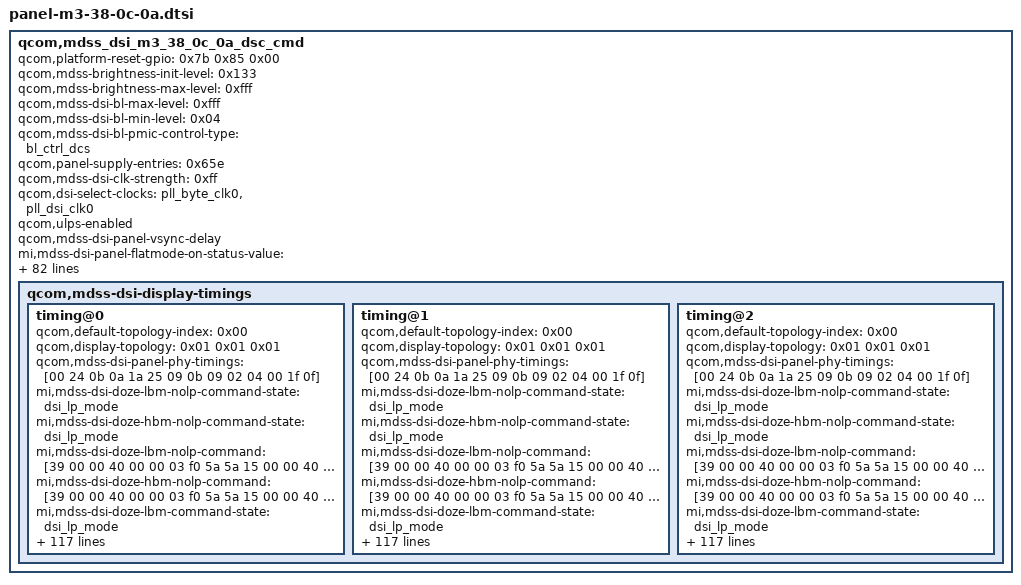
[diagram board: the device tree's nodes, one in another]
			qcom,mdss_dsi_m3_38_0c_0a_dsc_cmd {
				phandle = <0x676>;
				qcom,platform-reset-gpio = <0x7b 0x85 0x00>;
				qcom,mdss-brightness-init-level = <0x133>;
				qcom,mdss-brightness-max-level = <0xfff>;
				qcom,mdss-dsi-bl-max-level = <0xfff>;
				qcom,mdss-dsi-bl-min-level = <0x04>;
				qcom,mdss-dsi-bl-pmic-control-type = "bl_ctrl_dcs";
				qcom,panel-supply-entries = <0x65e>;
				qcom,mdss-dsi-clk-strength = <0xff>;
				qcom,dsi-select-clocks = "pll_byte_clk0", "pll_dsi_clk0";
				qcom,ulps-enabled;
				qcom,mdss-dsi-panel-vsync-delay;
				mi,mdss-dsi-panel-flatmode-on-status-value = <0x25>;
				mi,mdss-dsi-panel-flatmode-status-read-length = <0x01>;
				mi,mdss-dsi-panel-flatmode-status-offset-end-command-state = "dsi_lp_mode";
				mi,mdss-dsi-panel-flatmode-status-offset-end-command = [39 00 00 00 00 00 03 f0 a5 a5];
				mi,mdss-dsi-panel-flatmode-status-command-state = "dsi_lp_mode";
				mi,mdss-dsi-panel-flatmode-status-command = <0x6010001 0x192>;
				mi,mdss-dsi-panel-flatmode-status-offset-command-state = "dsi_lp_mode";
				mi,mdss-dsi-panel-flatmode-status-offset-command = [39 00 00 40 00 00 03 f0 5a 5a 39 00 00 00 00 00 04 b0 02 79 92];
				mi,flatmode-status-check-enabled;
				mi,normal-to-aod-doze-51reg-update-value = <0x995>;
				mi,dc-feature-type = "crc_skip_backlight";
				mi,thermal-dimming-flag;
				mi,dc-feature-enabled;
				mi,mdss-dsi-panel-dc-threshold = <0x1c2>;
				mi,mdss-fac-brightness-max-level = <0x7ff>;
				mi,mdss-dsi-fac-bl-max-level = <0x7ff>;
				mi,max-brightness-clone = <0x3fff>;
				mi,doze-lbm-dbv-level = <0x15>;
				mi,doze-hbm-dbv-level = <0xf3>;
				mi,panel-on-dimming-delay = <0x78>;
				mi,mdss-dsi-panel-wp-read-length = <0x04>;
				mi,mdss-dsi-panel-wp-read-command-state = "dsi_lp_mode";
				mi,mdss-dsi-panel-wp-read-command = <0x6010001 0x1a1>;
				mi,need-fod-animal-in-normal-enabled;
				mi,fod-low-brightness-lux-threshold = <0x01>;
				mi,fod-low-brightness-clone-threshold = <0x19b>;
				mi,local-hbm-ui-ready-delay-num-frame = <0x03>;
				mi,local-hbm-enabled;
				mi,panel-id = "", "", "M3", "8\f";
				mi,esd-err-irq-gpio = <0x7b 0x31 0x2008>;
				qcom,mdss-dsi-panel-blackness-level = <0xc9e>;
				qcom,mdss-dsi-panel-peak-brightness = <0x401640>;
				qcom,mdss-dsi-panel-hdr-color-primaries = <0x38a4 0x3c8c 0x7d00 0x4268 0x3c8c 0x7530 0x1f40 0xbb8>;
				qcom,mdss-dsi-panel-hdr-enabled;
				qcom,mdss-dsi-dma-schedule-window = <0x32>;
				qcom,mdss-dsi-dma-schedule-line = <0x01>;
				qcom,bl-update-flag = "delay_until_first_frame";
				qcom,mdss-dsi-bl-inverted-dbv;
				qcom,mdss-dsi-lp11-init;
				qcom,mdss-dsi-tx-eot-append;
				qcom,mdss-dsi-te-using-te-pin;
				qcom,mdss-dsi-te-check-enable;
				qcom,mdss-dsi-te-dcs-command = <0x01>;
				qcom,mdss-dsi-wr-mem-continue = <0x3c>;
				qcom,mdss-dsi-wr-mem-start = <0x2c>;
				qcom,mdss-dsi-te-pin-select = <0x01>;
				qcom,mdss-pan-physical-height-dimension = <0x93>;
				qcom,mdss-pan-physical-width-dimension = <0x42>;
				qcom,mdss-dsi-reset-sequence = <0x00 0x01 0x01 0x0a>;
				qcom,mdss-dsi-mdp-trigger = "none";
				qcom,mdss-dsi-dma-trigger = "trigger_sw";
				qcom,mdss-dsi-lane-3-state;
				qcom,mdss-dsi-lane-2-state;
				qcom,mdss-dsi-lane-1-state;
				qcom,mdss-dsi-lane-0-state;
				qcom,mdss-dsi-bllp-power-mode;
				qcom,mdss-dsi-bllp-eof-power-mode;
				qcom,mdss-dsi-lane-map = "lane_map_0123";
				qcom,mdss-dsi-traffic-mode = "burst_mode";
				qcom,dsi-phy-num = <0x00>;
				qcom,dsi-ctrl-num = <0x00>;
				qcom,mdss-dsi-border-color = <0x00>;
				qcom,mdss-dsi-underflow-color = <0xff>;
				qcom,mdss-dsi-color-order = "rgb_swap_rgb";
				qcom,mdss-dsi-bpp = <0x18>;
				qcom,mdss-dsi-stream = <0x00>;
				qcom,mdss-dsi-virtual-channel-id = <0x00>;
				qcom,mdss-dsi-panel-type = "dsi_cmd_mode";
				qcom,mdss-dsi-panel-name = "xiaomi m3 38 0c 0a sec cmd mode dsc dsi panel";

				qcom,mdss-dsi-display-timings {

					timing@0 {
						qcom,default-topology-index = <0x00>;
						qcom,display-topology = <0x01 0x01 0x01>;
						qcom,mdss-dsi-panel-phy-timings = [00 24 0b 0a 1a 25 09 0b 09 02 04 00 1f 0f];
						mi,mdss-dsi-doze-lbm-nolp-command-state = "dsi_lp_mode";
						mi,mdss-dsi-doze-hbm-nolp-command-state = "dsi_lp_mode";
						mi,mdss-dsi-doze-lbm-nolp-command = [39 00 00 40 00 00 03 f0 5a 5a 15 00 00 40 00 00 02 60 08 15 00 00 40 00 00 02 53 20 39 00 00 40 00 00 03 51 00 15 15 00 00 40 00 00 02 f7 0f 39 00 00 00 22 00 03 f0 a5 a5];
						mi,mdss-dsi-doze-hbm-nolp-command = [39 00 00 40 00 00 03 f0 5a 5a 15 00 00 40 00 00 02 60 08 15 00 00 40 00 00 02 53 20 39 00 00 40 00 00 03 51 00 f3 15 00 00 40 00 00 02 f7 0f 39 00 00 00 22 00 03 f0 a5 a5];
						mi,mdss-dsi-doze-lbm-command-state = "dsi_lp_mode";
						mi,mdss-dsi-doze-lbm-command-update = <0x51 0x00 0x02>;
						mi,mdss-dsi-doze-lbm-command = [39 00 00 20 00 00 03 51 09 95 39 00 00 40 00 00 03 f0 5a 5a 15 00 00 40 00 00 02 53 24 39 00 00 40 00 00 03 51 00 aa 15 00 00 40 00 00 02 f7 0f 39 00 00 00 00 00 03 f0 a5 a5];
						mi,mdss-dsi-doze-hbm-command-state = "dsi_lp_mode";
						mi,mdss-dsi-doze-hbm-command-update = <0x51 0x00 0x02>;
						mi,mdss-dsi-doze-hbm-command = [39 00 00 20 00 00 03 51 09 95 39 00 00 40 00 00 03 f0 5a 5a 15 00 00 40 00 00 02 53 24 39 00 00 40 00 00 03 51 07 ff 15 00 00 40 00 00 02 f7 0f 39 00 00 00 00 00 03 f0 a5 a5];
						mi,mdss-dsi-local-hbm-off-to-hbm-command-state = "dsi_lp_mode";
						mi,mdss-dsi-local-hbm-off-to-hbm-command-update = <0x51 0x02 0x02>;
						mi,mdss-dsi-local-hbm-off-to-hbm-command = [39 00 00 40 00 00 03 f0 5a 5a 15 00 00 40 00 00 02 53 20 39 00 00 40 00 00 03 51 00 00 39 00 00 00 00 00 03 f0 a5 a5];
						mi,mdss-dsi-local-hbm-off-to-normal-command-state = "dsi_lp_mode";
						mi,mdss-dsi-local-hbm-off-to-normal-command = [39 00 00 40 00 00 03 f0 5a 5a 15 00 00 40 00 00 02 53 20 39 00 00 00 00 00 03 f0 a5 a5];
						mi,mdss-dsi-local-hbm-normal-green-500nit-command-state = "dsi_hs_mode";
						mi,mdss-dsi-local-hbm-normal-green-500nit-command = [39 00 00 40 00 00 03 f0 5a 5a 39 00 00 40 00 00 04 b0 03 87 92 39 00 00 40 00 00 11 92 02 00 00 00 00 00 19 a7 e4 29 e8 e8 21 c8 66 60 39 00 00 40 00 00 04 b0 02 b4 98 39 00 00 40 00 00 03 98 00 00 39 00 00 40 00 00 04 b0 01 75 98 39 00 00 40 00 00 13 98 00 40 14 02 80 52 0a 41 48 1c 27 ff 80 0f ff ff ff ff 39 00 00 40 00 00 04 b0 02 5f 98 39 00 00 40 00 00 13 98 00 40 6f 09 80 d1 11 d1 86 1c 21 c2 7f f8 00 ff ff ff 39 00 00 40 00 00 04 b0 01 61 98 39 00 00 40 00 00 06 98 05 82 00 d5 00 39 00 00 40 00 00 04 b0 01 66 98 39 00 00 40 00 00 06 98 05 82 00 d5 00 39 00 00 40 00 00 04 b0 01 70 98 39 00 00 40 00 00 06 98 09 9d ef ff 23 39 00 00 40 00 00 04 b0 01 bd 98 39 00 00 40 00 00 37 98 15 62 09 2c 63 c2 52 27 0a 80 08 00 80 08 00 80 08 00 15 62 09 2c 63 c2 52 27 0a 80 08 00 80 08 00 80 08 00 15 62 09 2c 63 c2 52 27 0a 80 08 00 80 08 00 80 08 00 39 00 00 40 00 00 04 b0 01 f3 98 39 00 00 40 00 00 37 98 15 62 09 2c 63 c2 52 27 0a 80 08 00 80 08 00 80 08 00 15 62 09 2c 63 c2 52 27 0a 80 08 00 80 08 00 80 08 00 15 62 09 2c 63 c2 52 27 0a 80 08 00 80 08 00 80 08 00 39 00 00 40 00 00 04 b0 02 71 98 39 00 00 40 00 00 37 98 14 c1 ee 2b 43 c2 52 67 0a 80 08 00 80 08 00 80 08 00 14 a1 f3 2b 43 c2 52 67 0f 80 08 00 80 08 00 80 08 00 14 d1 f9 2b 43 c2 52 67 0a 80 08 00 80 08 00 80 08 00 39 00 00 40 00 00 02 53 30 39 00 00 00 00 00 03 f0 a5 a5];
						mi,mdss-dsi-local-hbm-hlpm-white-110nit-command-state = "dsi_hs_mode";
						mi,mdss-dsi-local-hbm-hlpm-white-110nit-command = [39 00 00 40 00 00 03 f0 5a 5a 39 00 00 40 00 00 02 53 20 39 00 00 00 22 00 03 f0 a5 a5 39 00 00 40 00 00 03 f0 5a 5a 39 00 00 40 00 00 04 b0 03 87 92 39 00 00 40 00 00 11 92 02 00 00 00 00 00 19 a7 e4 29 e8 e8 21 c8 66 60 39 00 00 40 00 00 04 b0 02 b4 98 39 00 00 40 00 00 03 98 00 00 39 00 00 40 00 00 04 b0 01 75 98 39 00 00 40 00 00 13 98 00 40 14 02 80 52 0a 41 48 1c 27 ff 80 0f ff ff ff ff 39 00 00 40 00 00 04 b0 02 5f 98 39 00 00 40 00 00 13 98 00 40 6f 09 80 d1 11 d1 86 1c 21 c2 7f f8 00 ff ff ff 39 00 00 40 00 00 04 b0 01 61 98 39 00 00 40 00 00 06 98 07 78 9c 34 e9 39 00 00 40 00 00 04 b0 01 66 98 39 00 00 40 00 00 06 98 07 78 9c 34 e9 39 00 00 40 00 00 04 b0 01 70 98 39 00 00 40 00 00 06 98 09 9d ef ff 23 39 00 00 40 00 00 04 b0 01 bd 98 39 00 00 40 00 00 37 98 15 62 09 2c 63 c2 52 27 0a 80 08 00 80 08 00 80 08 00 15 62 09 2c 63 c2 52 27 0a 80 08 00 80 08 00 80 08 00 15 62 09 2c 63 c2 52 27 0a 80 08 00 80 08 00 80 08 00 39 00 00 40 00 00 04 b0 01 f3 98 39 00 00 40 00 00 37 98 15 62 09 2c 63 c2 52 27 0a 80 08 00 80 08 00 80 08 00 15 62 09 2c 63 c2 52 27 0a 80 08 00 80 08 00 80 08 00 15 62 09 2c 63 c2 52 27 0a 80 08 00 80 08 00 80 08 00 39 00 00 40 00 00 04 b0 02 71 98 39 00 00 40 00 00 37 98 14 c1 ee 2b 43 c2 52 67 0a 80 08 00 80 08 00 80 08 00 14 a1 f3 2b 43 c2 52 67 0f 80 08 00 80 08 00 80 08 00 14 d1 f9 2b 43 c2 52 67 0a 80 08 00 80 08 00 80 08 00 39 00 00 40 00 00 02 53 30 39 00 00 00 0a 00 03 f0 a5 a5];
						mi,mdss-dsi-local-hbm-normal-white-110nit-command-state = "dsi_hs_mode";
						mi,mdss-dsi-local-hbm-normal-white-110nit-command = [39 00 00 40 00 00 03 f0 5a 5a 39 00 00 40 00 00 04 b0 03 87 92 39 00 00 40 00 00 11 92 02 00 00 00 00 00 19 a7 e4 29 e8 e8 21 c8 66 60 39 00 00 40 00 00 04 b0 02 b4 98 39 00 00 40 00 00 03 98 00 00 39 00 00 40 00 00 04 b0 01 75 98 39 00 00 40 00 00 13 98 00 40 14 02 80 52 0a 41 48 1c 27 ff 80 0f ff ff ff ff 39 00 00 40 00 00 04 b0 02 5f 98 39 00 00 40 00 00 13 98 00 40 6f 09 80 d1 11 d1 86 1c 21 c2 7f f8 00 ff ff ff 39 00 00 40 00 00 04 b0 01 61 98 39 00 00 40 00 00 06 98 07 78 9c 34 e9 39 00 00 40 00 00 04 b0 01 66 98 39 00 00 40 00 00 06 98 07 78 9c 34 e9 39 00 00 40 00 00 04 b0 01 70 98 39 00 00 40 00 00 06 98 09 9d ef ff 23 39 00 00 40 00 00 04 b0 01 bd 98 39 00 00 40 00 00 37 98 15 62 09 2c 63 c2 52 27 0a 80 08 00 80 08 00 80 08 00 15 62 09 2c 63 c2 52 27 0a 80 08 00 80 08 00 80 08 00 15 62 09 2c 63 c2 52 27 0a 80 08 00 80 08 00 80 08 00 39 00 00 40 00 00 04 b0 01 f3 98 39 00 00 40 00 00 37 98 15 62 09 2c 63 c2 52 27 0a 80 08 00 80 08 00 80 08 00 15 62 09 2c 63 c2 52 27 0a 80 08 00 80 08 00 80 08 00 15 62 09 2c 63 c2 52 27 0a 80 08 00 80 08 00 80 08 00 39 00 00 40 00 00 04 b0 02 71 98 39 00 00 40 00 00 37 98 14 c1 ee 2b 43 c2 52 67 0a 80 08 00 80 08 00 80 08 00 14 a1 f3 2b 43 c2 52 67 0f 80 08 00 80 08 00 80 08 00 14 d1 f9 2b 43 c2 52 67 0a 80 08 00 80 08 00 80 08 00 39 00 00 40 00 00 02 53 30 39 00 00 00 00 00 03 f0 a5 a5];
						mi,mdss-dsi-local-hbm-hlpm-white-1000nit-command-state = "dsi_hs_mode";
						mi,mdss-dsi-local-hbm-hlpm-white-1000nit-command = [39 00 00 40 00 00 03 f0 5a 5a 39 00 00 40 00 00 02 53 20 39 00 00 00 22 00 03 f0 a5 a5 39 00 00 40 00 00 03 f0 5a 5a 39 00 00 40 00 00 04 b0 03 87 92 39 00 00 40 00 00 11 92 02 00 00 00 00 00 19 a7 e4 29 e8 e8 21 c8 66 60 39 00 00 40 00 00 04 b0 02 b4 98 39 00 00 40 00 00 03 98 00 00 39 00 00 40 00 00 04 b0 01 75 98 39 00 00 40 00 00 13 98 00 40 14 02 80 52 0a 41 48 1c 27 ff 80 0f ff ff ff ff 39 00 00 40 00 00 04 b0 02 5f 98 39 00 00 40 00 00 13 98 00 40 6f 09 80 d1 11 d1 86 1c 21 c2 7f f8 00 ff ff ff 39 00 00 40 00 00 04 b0 01 61 98 39 00 00 40 00 00 06 98 09 9d ef 7f 23 39 00 00 40 00 00 04 b0 01 66 98 39 00 00 40 00 00 06 98 09 9d ef 7f 23 39 00 00 40 00 00 04 b0 01 70 98 39 00 00 40 00 00 06 98 09 9d ef ff 23 39 00 00 40 00 00 04 b0 01 bd 98 39 00 00 40 00 00 37 98 15 62 09 2c 63 c2 52 27 0a 80 08 00 80 08 00 80 08 00 15 62 09 2c 63 c2 52 27 0a 80 08 00 80 08 00 80 08 00 15 62 09 2c 63 c2 52 27 0a 80 08 00 80 08 00 80 08 00 39 00 00 40 00 00 04 b0 01 f3 98 39 00 00 40 00 00 37 98 15 62 09 2c 63 c2 52 27 0a 80 08 00 80 08 00 80 08 00 15 62 09 2c 63 c2 52 27 0a 80 08 00 80 08 00 80 08 00 15 62 09 2c 63 c2 52 27 0a 80 08 00 80 08 00 80 08 00 39 00 00 40 00 00 04 b0 02 71 98 39 00 00 40 00 00 37 98 14 c1 ee 2b 43 c2 52 67 0a 80 08 00 80 08 00 80 08 00 14 a1 f3 2b 43 c2 52 67 0f 80 08 00 80 08 00 80 08 00 14 d1 f9 2b 43 c2 52 67 0a 80 08 00 80 08 00 80 08 00 39 00 00 40 00 00 02 53 30 39 00 00 00 0a 00 03 f0 a5 a5];
						mi,mdss-dsi-local-hbm-normal-white-1000nit-command-state = "dsi_hs_mode";
						mi,mdss-dsi-local-hbm-normal-white-1000nit-command-update = <0x51 0x16 0x02>;
						mi,mdss-dsi-local-hbm-normal-white-1000nit-command = <0x39000040 0x3f0 0x5a5a3900 0x400000 0x4b00387 0x92390000 0x40000011 0x92020000 0x19 0xa7e429e8 0xe821c866 0x60390000 0x40000004 0xb002b498 0x39000040 0x398 0x3900 0x400000 0x4b00175 0x98390000 0x40000013 0x98004014 0x280520a 0x41481c27 0xff800fff 0xffffff39 0x4000 0x4b002 0x5f983900 0x400000 0x13980040 0x6f0980d1 0x11d1861c 0x21c27ff8 0xffffff 0x39000040 0x4b0 0x1619839 0x4000 0x69809 0x9def7f23 0x39000040 0x4b0 0x1669839 0x4000 0x69809 0x9def7f23 0x39000040 0x4b0 0x1709839 0x4000 0x69809 0x9defff23 0x39000040 0x4b0 0x1bd9839 0x4000 0x379815 0x62092c63 0xc252270a 0x80080080 0x8008008 0x156209 0x2c63c252 0x270a8008 0x800800 0x80080015 0x62092c63 0xc252270a 0x80080080 0x8008008 0x390000 0x40000004 0xb001f398 0x39000040 0x3798 0x1562092c 0x63c25227 0xa800800 0x80080080 0x8001562 0x92c63c2 0x52270a80 0x8008008 0x800800 0x1562092c 0x63c25227 0xa800800 0x80080080 0x8003900 0x400000 0x4b00271 0x98390000 0x40000037 0x9814c1ee 0x2b43c252 0x670a8008 0x800800 0x80080014 0xa1f32b43 0xc252670f 0x80080080 0x8008008 0x14d1f9 0x2b43c252 0x670a8008 0x800800 0x80080039 0x4000 0x25330 0x39000040 0x351 0x3900 0x00 0x3f0a5a5>;
						mi,mdss-dsi-flat-mode-off-command-state = "dsi_lp_mode";
						mi,mdss-dsi-flat-mode-off-command = <0x39000040 0x3f0 0x5a5a3900 0x400000 0x4b00279 0x92150000 0x40000002 0x92053900 0x00 0x3f0a5a5>;
						mi,mdss-dsi-flat-mode-on-command-state = "dsi_lp_mode";
						mi,mdss-dsi-flat-mode-on-command = <0x39000040 0x3f0 0x5a5a3900 0x400000 0x4b00279 0x92150000 0x40000002 0x92253900 0x00 0x3f0a5a5>;
						mi,mdss-dsi-hbm-fod-off-command-state = "dsi_lp_mode";
						mi,mdss-dsi-hbm-fod-off-command-update = <0x51 0x01 0x02>;
						mi,mdss-dsi-hbm-fod-off-command = [39 00 00 40 00 00 03 f0 5a 5a 39 00 00 40 00 00 03 51 07 ff 15 00 00 40 00 00 02 f7 0f 39 00 00 00 00 00 03 f0 a5 a5];
						mi,mdss-dsi-hbm-fod-on-command-state = "dsi_lp_mode";
						mi,mdss-dsi-hbm-fod-on-command = [39 00 00 40 00 00 03 f0 5a 5a 39 00 00 40 00 00 03 51 0f ff 15 00 00 40 00 00 02 f7 0f 39 00 00 00 00 00 03 f0 a5 a5];
						mi,mdss-dsi-hbm-off-command-state = "dsi_lp_mode";
						mi,mdss-dsi-hbm-off-command-update = <0x51 0x01 0x02>;
						mi,mdss-dsi-hbm-off-command = [39 00 00 40 00 00 03 f0 5a 5a 39 00 00 40 00 00 03 51 07 ff 15 00 00 40 00 00 02 f7 0f 39 00 00 00 00 00 03 f0 a5 a5];
						mi,mdss-dsi-hbm-on-command-state = "dsi_lp_mode";
						mi,mdss-dsi-hbm-on-command = [39 00 00 40 00 00 03 f0 5a 5a 39 00 00 40 00 00 03 51 07 ff 15 00 00 40 00 00 02 f7 0f 39 00 00 00 00 00 03 f0 a5 a5];
						mi,mdss-dsi-dimmingoff-command-state = "dsi_hs_mode";
						mi,mdss-dsi-dimmingoff-command = [15 00 00 00 00 00 02 53 20];
						mi,mdss-dsi-dimmingon-command-state = "dsi_hs_mode";
						mi,mdss-dsi-dimmingon-command = [15 00 00 00 00 00 02 53 28];
						qcom,mdss-dsi-off-command-state = "dsi_lp_mode";
						qcom,mdss-dsi-off-command = [39 00 00 40 00 00 03 f0 5a 5a 05 00 00 00 14 00 02 28 00 39 00 00 40 00 00 04 b0 00 4e 98 39 00 00 40 00 00 04 98 01 09 80 39 00 00 40 00 00 04 b0 00 0f f6 15 00 00 40 00 00 02 f6 02 15 00 00 40 00 00 02 f7 0f 39 00 00 00 64 00 03 f0 a5 a5 05 00 00 00 78 00 02 10 00];
						qcom,mdss-dsc-block-prediction-enable;
						qcom,mdss-dsc-bit-per-pixel = <0x08>;
						qcom,mdss-dsc-bit-per-component = <0x08>;
						qcom,mdss-dsc-slice-per-pkt = <0x02>;
						qcom,mdss-dsc-slice-width = <0x21c>;
						qcom,mdss-dsc-slice-height = <0x28>;
						qcom,compression-mode = "dsc";
						qcom,mdss-dsi-nolp-command-state = "dsi_lp_mode";
						qcom,mdss-dsi-nolp-command-update = <0x51 0x03 0x02>;
						qcom,mdss-dsi-nolp-command = [39 00 00 40 00 00 03 f0 5a 5a 15 00 00 40 00 00 02 60 08 15 00 00 40 00 00 02 53 20 39 00 00 40 00 00 03 51 00 00 15 00 00 40 00 00 02 f7 0f 39 00 00 00 22 00 03 f0 a5 a5];
						qcom,mdss-dsi-timing-switch-command-state = "dsi_hs_mode";
						qcom,mdss-dsi-timing-switch-command = [39 00 00 40 00 00 03 f0 5a 5a 15 00 00 40 00 00 02 60 08 39 00 00 40 00 00 04 b0 00 30 bd 15 00 00 40 00 00 02 bd 04 39 00 00 40 00 00 04 b0 00 16 f2 39 00 00 40 00 00 03 f2 01 70 15 00 00 40 00 00 02 f7 0f 39 00 00 00 00 00 03 f0 a5 a5];
						qcom,mdss-dsi-on-command-state = "dsi_lp_mode";
						qcom,mdss-dsi-on-command = [39 00 00 00 00 00 5a 9e 11 00 00 89 30 80 09 d8 04 38 00 28 02 1c 02 1c 02 00 02 3b 00 20 03 92 00 07 00 0e 02 e0 02 8b 18 00 10 f0 03 0c 20 00 06 0b 0b 33 0e 1c 2a 38 46 54 62 69 70 77 79 7b 7d 7e 01 02 01 00 09 40 09 be 19 fc 19 fa 19 f8 1a 38 1a 78 1a b6 2a b6 2a f4 2a f4 4b 34 63 74 00 15 00 00 00 00 00 02 9d 01 05 00 00 00 78 00 02 11 00 15 00 00 00 00 00 02 35 00 39 00 00 40 00 00 05 2a 00 00 04 37 39 00 00 00 00 00 05 2b 00 00 09 5f 39 00 00 40 00 00 03 f0 5a 5a 15 00 00 40 00 00 02 60 08 39 00 00 40 00 00 04 b0 00 30 bd 15 00 00 40 00 00 02 bd 04 39 00 00 40 00 00 04 b0 00 16 f2 39 00 00 40 00 00 03 f2 01 70 15 00 00 40 00 00 02 f7 0f 39 00 00 00 00 00 03 f0 a5 a5 39 00 00 40 00 00 03 f0 5a 5a 39 00 00 40 00 00 04 b0 00 36 c5 15 00 00 40 00 00 02 c5 11 39 00 00 40 00 00 04 b0 00 3a c5 39 00 00 40 00 00 03 c5 3f 21 39 00 00 40 00 00 04 b0 00 52 c5 39 00 00 40 00 00 03 c5 3f 21 39 00 00 00 00 00 03 f0 a5 a5 39 00 00 40 00 00 03 f0 5a 5a 39 00 00 40 00 00 04 b0 00 0d 94 15 00 00 40 00 00 02 94 20 15 00 00 40 00 00 02 53 28 39 00 00 40 00 00 03 51 00 00 15 00 00 40 00 00 02 f7 0f 39 00 00 00 00 00 03 f0 a5 a5 39 00 00 40 00 00 03 f0 5a 5a 15 00 00 40 00 00 02 e5 15 39 00 00 40 00 00 04 b0 00 3d f4 15 00 00 40 00 00 02 f4 f0 39 00 00 40 00 00 05 ed 43 49 42 03 39 00 00 00 00 00 03 f0 a5 a5 39 00 00 40 00 00 03 f0 5a 5a 39 00 00 40 00 00 04 b0 00 0a b1 39 00 00 40 00 00 04 b1 18 48 20 39 00 00 00 00 00 03 f0 a5 a5 39 00 00 40 00 00 03 f0 5a 5a 39 00 00 40 00 00 04 b0 01 64 92 39 00 00 40 00 00 02 92 70 39 00 00 00 00 00 03 f0 a5 a5 39 00 00 40 00 00 03 f0 5a 5a 39 00 00 40 00 00 04 b0 02 7e 92 15 00 00 40 00 00 02 92 0f 39 00 00 00 00 00 03 f0 a5 a5 39 00 00 40 00 00 03 f0 5a 5a 39 00 00 40 00 00 02 bb 30 39 00 00 40 00 00 02 f7 0f 39 00 00 00 00 00 03 f0 a5 a5 39 00 00 40 00 00 03 f0 5a 5a 39 00 00 40 00 00 04 b0 00 20 f6 15 00 00 40 00 00 02 f6 f0 39 00 00 00 00 00 03 f0 a5 a5 39 00 00 40 00 00 03 f0 5a 5a 39 00 00 40 00 00 04 b0 00 4e 98 39 00 00 40 00 00 04 98 00 09 80 39 00 00 40 00 00 04 b0 00 0f f6 15 00 00 40 00 00 02 f6 10 39 00 00 00 14 00 02 f7 0f 05 00 00 40 00 00 02 29 00 39 00 00 00 00 00 03 f0 a5 a5];
						qcom,mdss-mdp-transfer-time-us = <0x1c84>;
						qcom,mdss-dsi-panel-jitter = <0x05 0x01>;
						qcom,mdss-dsi-panel-clockrate = <0x4190ab00>;
						qcom,mdss-dsi-v-bottom-border = <0x00>;
						qcom,mdss-dsi-v-top-border = <0x00>;
						qcom,mdss-dsi-h-right-border = <0x00>;
						qcom,mdss-dsi-h-left-border = <0x00>;
						qcom,mdss-dsi-h-sync-pulse = <0x00>;
						qcom,mdss-dsi-v-pulse-width = <0x18>;
						qcom,mdss-dsi-v-front-porch = <0x80>;
						qcom,mdss-dsi-v-back-porch = <0x84>;
						qcom,mdss-dsi-h-sync-skew = <0x00>;
						qcom,mdss-dsi-h-pulse-width = <0x20>;
						qcom,mdss-dsi-h-back-porch = <0x7c>;
						qcom,mdss-dsi-h-front-porch = <0x7c>;
						qcom,mdss-dsi-panel-height = <0x960>;
						qcom,mdss-dsi-panel-width = <0x438>;
						qcom,mdss-dsi-panel-framerate = <0x3c>;
						qcom,mdss-dsi-cmd-mode;
					};

					timing@1 {
						qcom,default-topology-index = <0x00>;
						qcom,display-topology = <0x01 0x01 0x01>;
						qcom,mdss-dsi-panel-phy-timings = [00 24 0b 0a 1a 25 09 0b 09 02 04 00 1f 0f];
						mi,mdss-dsi-doze-lbm-nolp-command-state = "dsi_lp_mode";
						mi,mdss-dsi-doze-hbm-nolp-command-state = "dsi_lp_mode";
						mi,mdss-dsi-doze-lbm-nolp-command = [39 00 00 40 00 00 03 f0 5a 5a 15 00 00 40 00 00 02 60 00 15 00 00 40 00 00 02 53 20 39 00 00 40 00 00 03 51 00 15 15 00 00 40 00 00 02 f7 0f 39 00 00 00 22 00 03 f0 a5 a5];
						mi,mdss-dsi-doze-hbm-nolp-command = [39 00 00 40 00 00 03 f0 5a 5a 15 00 00 40 00 00 02 60 00 15 00 00 40 00 00 02 53 20 39 00 00 40 00 00 03 51 00 f3 15 00 00 40 00 00 02 f7 0f 39 00 00 00 22 00 03 f0 a5 a5];
						mi,mdss-dsi-doze-lbm-command-state = "dsi_lp_mode";
						mi,mdss-dsi-doze-lbm-command-update = <0x51 0x00 0x02>;
						mi,mdss-dsi-doze-lbm-command = [39 00 00 20 00 00 03 51 09 95 39 00 00 40 00 00 03 f0 5a 5a 15 00 00 40 00 00 02 53 24 39 00 00 40 00 00 03 51 00 aa 15 00 00 40 00 00 02 f7 0f 39 00 00 00 00 00 03 f0 a5 a5];
						mi,mdss-dsi-doze-hbm-command-state = "dsi_lp_mode";
						mi,mdss-dsi-doze-hbm-command-update = <0x51 0x00 0x02>;
						mi,mdss-dsi-doze-hbm-command = [39 00 00 20 00 00 03 51 09 95 39 00 00 40 00 00 03 f0 5a 5a 15 00 00 40 00 00 02 53 24 39 00 00 40 00 00 03 51 07 ff 15 00 00 40 00 00 02 f7 0f 39 00 00 00 00 00 03 f0 a5 a5];
						mi,mdss-dsi-local-hbm-off-to-hbm-command-state = "dsi_lp_mode";
						mi,mdss-dsi-local-hbm-off-to-hbm-command-update = <0x51 0x02 0x02>;
						mi,mdss-dsi-local-hbm-off-to-hbm-command = [39 00 00 40 00 00 03 f0 5a 5a 15 00 00 40 00 00 02 53 20 39 00 00 40 00 00 03 51 00 00 39 00 00 00 00 00 03 f0 a5 a5];
						mi,mdss-dsi-local-hbm-off-to-normal-command-state = "dsi_lp_mode";
						mi,mdss-dsi-local-hbm-off-to-normal-command = [39 00 00 40 00 00 03 f0 5a 5a 15 00 00 40 00 00 02 53 20 39 00 00 00 00 00 03 f0 a5 a5];
						mi,mdss-dsi-local-hbm-normal-green-500nit-command-state = "dsi_hs_mode";
						mi,mdss-dsi-local-hbm-normal-green-500nit-command = [39 00 00 40 00 00 03 f0 5a 5a 39 00 00 40 00 00 04 b0 03 87 92 39 00 00 40 00 00 11 92 02 00 00 00 00 00 19 a7 e4 29 e8 e8 21 c8 66 60 39 00 00 40 00 00 04 b0 02 b4 98 39 00 00 40 00 00 03 98 00 00 39 00 00 40 00 00 04 b0 01 75 98 39 00 00 40 00 00 13 98 00 40 14 02 80 52 0a 41 48 1c 27 ff 80 0f ff ff ff ff 39 00 00 40 00 00 04 b0 02 5f 98 39 00 00 40 00 00 13 98 00 40 6f 09 80 d1 11 d1 86 1c 21 c2 7f f8 00 ff ff ff 39 00 00 40 00 00 04 b0 01 61 98 39 00 00 40 00 00 06 98 05 82 00 d5 00 39 00 00 40 00 00 04 b0 01 66 98 39 00 00 40 00 00 06 98 05 82 00 d5 00 39 00 00 40 00 00 04 b0 01 70 98 39 00 00 40 00 00 06 98 09 9d ef ff 23 39 00 00 40 00 00 04 b0 01 bd 98 39 00 00 40 00 00 37 98 15 62 09 2c 63 c2 52 27 0a 80 08 00 80 08 00 80 08 00 15 62 09 2c 63 c2 52 27 0a 80 08 00 80 08 00 80 08 00 15 62 09 2c 63 c2 52 27 0a 80 08 00 80 08 00 80 08 00 39 00 00 40 00 00 04 b0 01 f3 98 39 00 00 40 00 00 37 98 15 62 09 2c 63 c2 52 27 0a 80 08 00 80 08 00 80 08 00 15 62 09 2c 63 c2 52 27 0a 80 08 00 80 08 00 80 08 00 15 62 09 2c 63 c2 52 27 0a 80 08 00 80 08 00 80 08 00 39 00 00 40 00 00 04 b0 02 71 98 39 00 00 40 00 00 37 98 14 c1 ee 2b 43 c2 52 67 0a 80 08 00 80 08 00 80 08 00 14 a1 f3 2b 43 c2 52 67 0f 80 08 00 80 08 00 80 08 00 14 d1 f9 2b 43 c2 52 67 0a 80 08 00 80 08 00 80 08 00 39 00 00 40 00 00 02 53 30 39 00 00 00 00 00 03 f0 a5 a5];
						mi,mdss-dsi-local-hbm-hlpm-white-110nit-command-state = "dsi_hs_mode";
						mi,mdss-dsi-local-hbm-hlpm-white-110nit-command = [39 00 00 40 00 00 03 f0 5a 5a 39 00 00 40 00 00 02 53 20 39 00 00 00 22 00 03 f0 a5 a5 39 00 00 40 00 00 03 f0 5a 5a 39 00 00 40 00 00 04 b0 03 87 92 39 00 00 40 00 00 11 92 02 00 00 00 00 00 19 a7 e4 29 e8 e8 21 c8 66 60 39 00 00 40 00 00 04 b0 02 b4 98 39 00 00 40 00 00 03 98 00 00 39 00 00 40 00 00 04 b0 01 75 98 39 00 00 40 00 00 13 98 00 40 14 02 80 52 0a 41 48 1c 27 ff 80 0f ff ff ff ff 39 00 00 40 00 00 04 b0 02 5f 98 39 00 00 40 00 00 13 98 00 40 6f 09 80 d1 11 d1 86 1c 21 c2 7f f8 00 ff ff ff 39 00 00 40 00 00 04 b0 01 61 98 39 00 00 40 00 00 06 98 07 78 9c 34 e9 39 00 00 40 00 00 04 b0 01 66 98 39 00 00 40 00 00 06 98 07 78 9c 34 e9 39 00 00 40 00 00 04 b0 01 70 98 39 00 00 40 00 00 06 98 09 9d ef ff 23 39 00 00 40 00 00 04 b0 01 bd 98 39 00 00 40 00 00 37 98 15 62 09 2c 63 c2 52 27 0a 80 08 00 80 08 00 80 08 00 15 62 09 2c 63 c2 52 27 0a 80 08 00 80 08 00 80 08 00 15 62 09 2c 63 c2 52 27 0a 80 08 00 80 08 00 80 08 00 39 00 00 40 00 00 04 b0 01 f3 98 39 00 00 40 00 00 37 98 15 62 09 2c 63 c2 52 27 0a 80 08 00 80 08 00 80 08 00 15 62 09 2c 63 c2 52 27 0a 80 08 00 80 08 00 80 08 00 15 62 09 2c 63 c2 52 27 0a 80 08 00 80 08 00 80 08 00 39 00 00 40 00 00 04 b0 02 71 98 39 00 00 40 00 00 37 98 14 c1 ee 2b 43 c2 52 67 0a 80 08 00 80 08 00 80 08 00 14 a1 f3 2b 43 c2 52 67 0f 80 08 00 80 08 00 80 08 00 14 d1 f9 2b 43 c2 52 67 0a 80 08 00 80 08 00 80 08 00 39 00 00 40 00 00 02 53 30 39 00 00 00 0a 00 03 f0 a5 a5];
						mi,mdss-dsi-local-hbm-normal-white-110nit-command-state = "dsi_hs_mode";
						mi,mdss-dsi-local-hbm-normal-white-110nit-command = [39 00 00 40 00 00 03 f0 5a 5a 39 00 00 40 00 00 04 b0 03 87 92 39 00 00 40 00 00 11 92 02 00 00 00 00 00 19 a7 e4 29 e8 e8 21 c8 66 60 39 00 00 40 00 00 04 b0 02 b4 98 39 00 00 40 00 00 03 98 00 00 39 00 00 40 00 00 04 b0 01 75 98 39 00 00 40 00 00 13 98 00 40 14 02 80 52 0a 41 48 1c 27 ff 80 0f ff ff ff ff 39 00 00 40 00 00 04 b0 02 5f 98 39 00 00 40 00 00 13 98 00 40 6f 09 80 d1 11 d1 86 1c 21 c2 7f f8 00 ff ff ff 39 00 00 40 00 00 04 b0 01 61 98 39 00 00 40 00 00 06 98 07 78 9c 34 e9 39 00 00 40 00 00 04 b0 01 66 98 39 00 00 40 00 00 06 98 07 78 9c 34 e9 39 00 00 40 00 00 04 b0 01 70 98 39 00 00 40 00 00 06 98 09 9d ef ff 23 39 00 00 40 00 00 04 b0 01 bd 98 39 00 00 40 00 00 37 98 15 62 09 2c 63 c2 52 27 0a 80 08 00 80 08 00 80 08 00 15 62 09 2c 63 c2 52 27 0a 80 08 00 80 08 00 80 08 00 15 62 09 2c 63 c2 52 27 0a 80 08 00 80 08 00 80 08 00 39 00 00 40 00 00 04 b0 01 f3 98 39 00 00 40 00 00 37 98 15 62 09 2c 63 c2 52 27 0a 80 08 00 80 08 00 80 08 00 15 62 09 2c 63 c2 52 27 0a 80 08 00 80 08 00 80 08 00 15 62 09 2c 63 c2 52 27 0a 80 08 00 80 08 00 80 08 00 39 00 00 40 00 00 04 b0 02 71 98 39 00 00 40 00 00 37 98 14 c1 ee 2b 43 c2 52 67 0a 80 08 00 80 08 00 80 08 00 14 a1 f3 2b 43 c2 52 67 0f 80 08 00 80 08 00 80 08 00 14 d1 f9 2b 43 c2 52 67 0a 80 08 00 80 08 00 80 08 00 39 00 00 40 00 00 02 53 30 39 00 00 00 00 00 03 f0 a5 a5];
						mi,mdss-dsi-local-hbm-hlpm-white-1000nit-command-state = "dsi_hs_mode";
						mi,mdss-dsi-local-hbm-hlpm-white-1000nit-command = [39 00 00 40 00 00 03 f0 5a 5a 39 00 00 40 00 00 02 53 20 39 00 00 00 22 00 03 f0 a5 a5 39 00 00 40 00 00 03 f0 5a 5a 39 00 00 40 00 00 04 b0 03 87 92 39 00 00 40 00 00 11 92 02 00 00 00 00 00 19 a7 e4 29 e8 e8 21 c8 66 60 39 00 00 40 00 00 04 b0 02 b4 98 39 00 00 40 00 00 03 98 00 00 39 00 00 40 00 00 04 b0 01 75 98 39 00 00 40 00 00 13 98 00 40 14 02 80 52 0a 41 48 1c 27 ff 80 0f ff ff ff ff 39 00 00 40 00 00 04 b0 02 5f 98 39 00 00 40 00 00 13 98 00 40 6f 09 80 d1 11 d1 86 1c 21 c2 7f f8 00 ff ff ff 39 00 00 40 00 00 04 b0 01 61 98 39 00 00 40 00 00 06 98 09 9d ef 7f 23 39 00 00 40 00 00 04 b0 01 66 98 39 00 00 40 00 00 06 98 09 9d ef 7f 23 39 00 00 40 00 00 04 b0 01 70 98 39 00 00 40 00 00 06 98 09 9d ef ff 23 39 00 00 40 00 00 04 b0 01 bd 98 39 00 00 40 00 00 37 98 15 62 09 2c 63 c2 52 27 0a 80 08 00 80 08 00 80 08 00 15 62 09 2c 63 c2 52 27 0a 80 08 00 80 08 00 80 08 00 15 62 09 2c 63 c2 52 27 0a 80 08 00 80 08 00 80 08 00 39 00 00 40 00 00 04 b0 01 f3 98 39 00 00 40 00 00 37 98 15 62 09 2c 63 c2 52 27 0a 80 08 00 80 08 00 80 08 00 15 62 09 2c 63 c2 52 27 0a 80 08 00 80 08 00 80 08 00 15 62 09 2c 63 c2 52 27 0a 80 08 00 80 08 00 80 08 00 39 00 00 40 00 00 04 b0 02 71 98 39 00 00 40 00 00 37 98 14 c1 ee 2b 43 c2 52 67 0a 80 08 00 80 08 00 80 08 00 14 a1 f3 2b 43 c2 52 67 0f 80 08 00 80 08 00 80 08 00 14 d1 f9 2b 43 c2 52 67 0a 80 08 00 80 08 00 80 08 00 39 00 00 40 00 00 02 53 30 39 00 00 00 0a 00 03 f0 a5 a5];
						mi,mdss-dsi-local-hbm-normal-white-1000nit-command-state = "dsi_hs_mode";
						mi,mdss-dsi-local-hbm-normal-white-1000nit-command-update = <0x51 0x16 0x02>;
						mi,mdss-dsi-local-hbm-normal-white-1000nit-command = <0x39000040 0x3f0 0x5a5a3900 0x400000 0x4b00387 0x92390000 0x40000011 0x92020000 0x19 0xa7e429e8 0xe821c866 0x60390000 0x40000004 0xb002b498 0x39000040 0x398 0x3900 0x400000 0x4b00175 0x98390000 0x40000013 0x98004014 0x280520a 0x41481c27 0xff800fff 0xffffff39 0x4000 0x4b002 0x5f983900 0x400000 0x13980040 0x6f0980d1 0x11d1861c 0x21c27ff8 0xffffff 0x39000040 0x4b0 0x1619839 0x4000 0x69809 0x9def7f23 0x39000040 0x4b0 0x1669839 0x4000 0x69809 0x9def7f23 0x39000040 0x4b0 0x1709839 0x4000 0x69809 0x9defff23 0x39000040 0x4b0 0x1bd9839 0x4000 0x379815 0x62092c63 0xc252270a 0x80080080 0x8008008 0x156209 0x2c63c252 0x270a8008 0x800800 0x80080015 0x62092c63 0xc252270a 0x80080080 0x8008008 0x390000 0x40000004 0xb001f398 0x39000040 0x3798 0x1562092c 0x63c25227 0xa800800 0x80080080 0x8001562 0x92c63c2 0x52270a80 0x8008008 0x800800 0x1562092c 0x63c25227 0xa800800 0x80080080 0x8003900 0x400000 0x4b00271 0x98390000 0x40000037 0x9814c1ee 0x2b43c252 0x670a8008 0x800800 0x80080014 0xa1f32b43 0xc252670f 0x80080080 0x8008008 0x14d1f9 0x2b43c252 0x670a8008 0x800800 0x80080039 0x4000 0x25330 0x39000040 0x351 0x3900 0x00 0x3f0a5a5>;
						mi,mdss-dsi-flat-mode-off-command-state = "dsi_lp_mode";
						mi,mdss-dsi-flat-mode-off-command = <0x39000040 0x3f0 0x5a5a3900 0x400000 0x4b00279 0x92150000 0x40000002 0x92053900 0x00 0x3f0a5a5>;
						mi,mdss-dsi-flat-mode-on-command-state = "dsi_lp_mode";
						mi,mdss-dsi-flat-mode-on-command = <0x39000040 0x3f0 0x5a5a3900 0x400000 0x4b00279 0x92150000 0x40000002 0x92253900 0x00 0x3f0a5a5>;
						mi,mdss-dsi-hbm-fod-off-command-state = "dsi_lp_mode";
						mi,mdss-dsi-hbm-fod-off-command-update = <0x51 0x01 0x02>;
						mi,mdss-dsi-hbm-fod-off-command = [39 00 00 40 00 00 03 f0 5a 5a 39 00 00 40 00 00 03 51 07 ff 15 00 00 40 00 00 02 f7 0f 39 00 00 00 00 00 03 f0 a5 a5];
						mi,mdss-dsi-hbm-fod-on-command-state = "dsi_lp_mode";
						mi,mdss-dsi-hbm-fod-on-command = [39 00 00 40 00 00 03 f0 5a 5a 39 00 00 40 00 00 03 51 0f ff 15 00 00 40 00 00 02 f7 0f 39 00 00 00 00 00 03 f0 a5 a5];
						mi,mdss-dsi-hbm-off-command-state = "dsi_lp_mode";
						mi,mdss-dsi-hbm-off-command-update = <0x51 0x01 0x02>;
						mi,mdss-dsi-hbm-off-command = [39 00 00 40 00 00 03 f0 5a 5a 39 00 00 40 00 00 03 51 07 ff 15 00 00 40 00 00 02 f7 0f 39 00 00 00 00 00 03 f0 a5 a5];
						mi,mdss-dsi-hbm-on-command-state = "dsi_lp_mode";
						mi,mdss-dsi-hbm-on-command = [39 00 00 40 00 00 03 f0 5a 5a 39 00 00 40 00 00 03 51 07 ff 15 00 00 40 00 00 02 f7 0f 39 00 00 00 00 00 03 f0 a5 a5];
						mi,mdss-dsi-dimmingoff-command-state = "dsi_hs_mode";
						mi,mdss-dsi-dimmingoff-command = [15 00 00 00 00 00 02 53 20];
						mi,mdss-dsi-dimmingon-command-state = "dsi_hs_mode";
						mi,mdss-dsi-dimmingon-command = [15 00 00 00 00 00 02 53 28];
						qcom,mdss-dsi-off-command-state = "dsi_lp_mode";
						qcom,mdss-dsi-off-command = [39 00 00 40 00 00 03 f0 5a 5a 05 00 00 00 14 00 02 28 00 39 00 00 40 00 00 04 b0 00 4e 98 39 00 00 40 00 00 04 98 01 09 80 39 00 00 40 00 00 04 b0 00 0f f6 15 00 00 40 00 00 02 f6 02 15 00 00 40 00 00 02 f7 0f 39 00 00 00 64 00 03 f0 a5 a5 05 00 00 00 78 00 02 10 00];
						qcom,mdss-dsc-block-prediction-enable;
						qcom,mdss-dsc-bit-per-pixel = <0x08>;
						qcom,mdss-dsc-bit-per-component = <0x08>;
						qcom,mdss-dsc-slice-per-pkt = <0x02>;
						qcom,mdss-dsc-slice-width = <0x21c>;
						qcom,mdss-dsc-slice-height = <0x28>;
						qcom,compression-mode = "dsc";
						qcom,mdss-dsi-nolp-command-state = "dsi_lp_mode";
						qcom,mdss-dsi-nolp-command-update = <0x51 0x03 0x02>;
						qcom,mdss-dsi-nolp-command = [39 00 00 40 00 00 03 f0 5a 5a 15 00 00 40 00 00 02 60 00 15 00 00 40 00 00 02 53 20 39 00 00 40 00 00 03 51 00 00 15 00 00 40 00 00 02 f7 0f 39 00 00 00 22 00 03 f0 a5 a5];
						qcom,mdss-dsi-timing-switch-command-state = "dsi_hs_mode";
						qcom,mdss-dsi-timing-switch-command = [39 00 00 40 00 00 03 f0 5a 5a 15 00 00 40 00 00 02 60 00 39 00 00 40 00 00 04 b0 00 30 bd 15 00 00 40 00 00 02 bd 04 39 00 00 40 00 00 04 b0 00 16 f2 39 00 00 40 00 00 03 f2 01 70 15 00 00 40 00 00 02 f7 0f 39 00 00 00 00 00 03 f0 a5 a5];
						qcom,mdss-dsi-on-command-state = "dsi_lp_mode";
						qcom,mdss-dsi-on-command = [39 00 00 00 00 00 5a 9e 11 00 00 89 30 80 09 d8 04 38 00 28 02 1c 02 1c 02 00 02 3b 00 20 03 92 00 07 00 0e 02 e0 02 8b 18 00 10 f0 03 0c 20 00 06 0b 0b 33 0e 1c 2a 38 46 54 62 69 70 77 79 7b 7d 7e 01 02 01 00 09 40 09 be 19 fc 19 fa 19 f8 1a 38 1a 78 1a b6 2a b6 2a f4 2a f4 4b 34 63 74 00 15 00 00 00 00 00 02 9d 01 05 00 00 00 78 00 02 11 00 15 00 00 00 00 00 02 35 00 39 00 00 40 00 00 05 2a 00 00 04 37 39 00 00 00 00 00 05 2b 00 00 09 5f 39 00 00 40 00 00 03 f0 5a 5a 15 00 00 40 00 00 02 60 00 39 00 00 40 00 00 04 b0 00 30 bd 15 00 00 40 00 00 02 bd 04 39 00 00 40 00 00 04 b0 00 16 f2 39 00 00 40 00 00 03 f2 01 70 15 00 00 40 00 00 02 f7 0f 39 00 00 00 00 00 03 f0 a5 a5 39 00 00 40 00 00 03 f0 5a 5a 39 00 00 40 00 00 04 b0 00 36 c5 15 00 00 40 00 00 02 c5 11 39 00 00 40 00 00 04 b0 00 3a c5 39 00 00 40 00 00 03 c5 3f 21 39 00 00 40 00 00 04 b0 00 52 c5 39 00 00 40 00 00 03 c5 3f 21 39 00 00 00 00 00 03 f0 a5 a5 39 00 00 40 00 00 03 f0 5a 5a 39 00 00 40 00 00 04 b0 00 0d 94 15 00 00 40 00 00 02 94 20 15 00 00 40 00 00 02 53 28 39 00 00 40 00 00 03 51 00 00 15 00 00 40 00 00 02 f7 0f 39 00 00 00 00 00 03 f0 a5 a5 39 00 00 40 00 00 03 f0 5a 5a 15 00 00 40 00 00 02 e5 15 39 00 00 40 00 00 04 b0 00 3d f4 15 00 00 40 00 00 02 f4 f0 39 00 00 40 00 00 05 ed 43 49 42 03 39 00 00 00 00 00 03 f0 a5 a5 39 00 00 40 00 00 03 f0 5a 5a 39 00 00 40 00 00 04 b0 00 0a b1 39 00 00 40 00 00 04 b1 18 48 20 39 00 00 00 00 00 03 f0 a5 a5 39 00 00 40 00 00 03 f0 5a 5a 39 00 00 40 00 00 04 b0 01 64 92 39 00 00 40 00 00 02 92 70 39 00 00 00 00 00 03 f0 a5 a5 39 00 00 40 00 00 03 f0 5a 5a 39 00 00 40 00 00 04 b0 02 7e 92 15 00 00 40 00 00 02 92 0f 39 00 00 00 00 00 03 f0 a5 a5 39 00 00 40 00 00 03 f0 5a 5a 39 00 00 40 00 00 02 bb 30 39 00 00 40 00 00 02 f7 0f 39 00 00 00 00 00 03 f0 a5 a5 39 00 00 40 00 00 03 f0 5a 5a 39 00 00 40 00 00 04 b0 00 20 f6 15 00 00 40 00 00 02 f6 f0 39 00 00 00 00 00 03 f0 a5 a5 39 00 00 40 00 00 03 f0 5a 5a 39 00 00 40 00 00 04 b0 00 4e 98 39 00 00 40 00 00 04 98 00 09 80 39 00 00 40 00 00 04 b0 00 0f f6 15 00 00 40 00 00 02 f6 10 39 00 00 00 14 00 02 f7 0f 05 00 00 40 00 00 02 29 00 39 00 00 00 00 00 03 f0 a5 a5];
						qcom,mdss-mdp-transfer-time-us = <0x1c84>;
						qcom,mdss-dsi-panel-jitter = <0x05 0x01>;
						qcom,mdss-dsi-panel-clockrate = <0x4190ab00>;
						qcom,mdss-dsi-v-bottom-border = <0x00>;
						qcom,mdss-dsi-v-top-border = <0x00>;
						qcom,mdss-dsi-h-right-border = <0x00>;
						qcom,mdss-dsi-h-left-border = <0x00>;
						qcom,mdss-dsi-h-sync-pulse = <0x00>;
						qcom,mdss-dsi-v-pulse-width = <0x18>;
						qcom,mdss-dsi-v-front-porch = <0x80>;
						qcom,mdss-dsi-v-back-porch = <0x84>;
						qcom,mdss-dsi-h-sync-skew = <0x00>;
						qcom,mdss-dsi-h-pulse-width = <0x20>;
						qcom,mdss-dsi-h-back-porch = <0x7c>;
						qcom,mdss-dsi-h-front-porch = <0x7c>;
						qcom,mdss-dsi-panel-height = <0x960>;
						qcom,mdss-dsi-panel-width = <0x438>;
						qcom,mdss-dsi-panel-framerate = <0x78>;
						qcom,mdss-dsi-cmd-mode;
					};

					timing@2 {
						qcom,default-topology-index = <0x00>;
						qcom,display-topology = <0x01 0x01 0x01>;
						qcom,mdss-dsi-panel-phy-timings = [00 24 0b 0a 1a 25 09 0b 09 02 04 00 1f 0f];
						mi,mdss-dsi-doze-lbm-nolp-command-state = "dsi_lp_mode";
						mi,mdss-dsi-doze-hbm-nolp-command-state = "dsi_lp_mode";
						mi,mdss-dsi-doze-lbm-nolp-command = [39 00 00 40 00 00 03 f0 5a 5a 15 00 00 40 00 00 02 60 00 39 00 00 40 00 00 04 b0 00 16 f2 39 00 00 40 00 00 03 f2 01 ea 15 00 00 40 00 00 02 53 20 39 00 00 40 00 00 03 51 00 15 15 00 00 40 00 00 02 f7 0f 39 00 00 00 22 00 03 f0 a5 a5];
						mi,mdss-dsi-doze-hbm-nolp-command = [39 00 00 40 00 00 03 f0 5a 5a 15 00 00 40 00 00 02 60 00 39 00 00 40 00 00 04 b0 00 16 f2 39 00 00 40 00 00 03 f2 01 ea 15 00 00 40 00 00 02 53 20 39 00 00 40 00 00 03 51 00 f3 15 00 00 40 00 00 02 f7 0f 39 00 00 00 22 00 03 f0 a5 a5];
						mi,mdss-dsi-doze-lbm-command-state = "dsi_lp_mode";
						mi,mdss-dsi-doze-lbm-command-update = <0x51 0x00 0x02>;
						mi,mdss-dsi-doze-lbm-command = [39 00 00 20 00 00 03 51 09 95 39 00 00 40 00 00 03 f0 5a 5a 15 00 00 40 00 00 02 53 24 39 00 00 40 00 00 03 51 00 f6 15 00 00 40 00 00 02 f7 0f 39 00 00 00 00 00 03 f0 a5 a5];
						mi,mdss-dsi-doze-hbm-command-state = "dsi_lp_mode";
						mi,mdss-dsi-doze-hbm-command-update = <0x51 0x00 0x02>;
						mi,mdss-dsi-doze-hbm-command = [39 00 00 20 00 00 03 51 09 95 39 00 00 40 00 00 03 f0 5a 5a 15 00 00 40 00 00 02 53 24 39 00 00 40 00 00 03 51 07 ff 15 00 00 40 00 00 02 f7 0f 39 00 00 00 00 00 03 f0 a5 a5];
						mi,mdss-dsi-local-hbm-off-to-hbm-command-state = "dsi_lp_mode";
						mi,mdss-dsi-local-hbm-off-to-hbm-command-update = <0x51 0x02 0x02>;
						mi,mdss-dsi-local-hbm-off-to-hbm-command = [39 00 00 40 00 00 03 f0 5a 5a 15 00 00 40 00 00 02 53 20 39 00 00 40 00 00 03 51 00 00 39 00 00 00 00 00 03 f0 a5 a5];
						mi,mdss-dsi-local-hbm-off-to-normal-command-state = "dsi_lp_mode";
						mi,mdss-dsi-local-hbm-off-to-normal-command = [39 00 00 40 00 00 03 f0 5a 5a 15 00 00 40 00 00 02 53 20 39 00 00 00 00 00 03 f0 a5 a5];
						mi,mdss-dsi-local-hbm-normal-green-500nit-command-state = "dsi_hs_mode";
						mi,mdss-dsi-local-hbm-normal-green-500nit-command = [39 00 00 40 00 00 03 f0 5a 5a 39 00 00 40 00 00 04 b0 03 87 92 39 00 00 40 00 00 11 92 02 00 00 00 00 00 19 a7 e4 29 e8 e8 21 c8 66 60 39 00 00 40 00 00 04 b0 02 b4 98 39 00 00 40 00 00 03 98 00 00 39 00 00 40 00 00 04 b0 01 75 98 39 00 00 40 00 00 13 98 00 40 14 02 80 52 0a 41 48 1c 27 ff 80 0f ff ff ff ff 39 00 00 40 00 00 04 b0 02 5f 98 39 00 00 40 00 00 13 98 00 40 6f 09 80 d1 11 d1 86 1c 21 c2 7f f8 00 ff ff ff 39 00 00 40 00 00 04 b0 01 61 98 39 00 00 40 00 00 06 98 05 82 00 d5 00 39 00 00 40 00 00 04 b0 01 66 98 39 00 00 40 00 00 06 98 05 82 00 d5 00 39 00 00 40 00 00 04 b0 01 70 98 39 00 00 40 00 00 06 98 09 9d ef ff 23 39 00 00 40 00 00 04 b0 01 bd 98 39 00 00 40 00 00 37 98 15 62 09 2c 63 c2 52 27 0a 80 08 00 80 08 00 80 08 00 15 62 09 2c 63 c2 52 27 0a 80 08 00 80 08 00 80 08 00 15 62 09 2c 63 c2 52 27 0a 80 08 00 80 08 00 80 08 00 39 00 00 40 00 00 04 b0 01 f3 98 39 00 00 40 00 00 37 98 15 62 09 2c 63 c2 52 27 0a 80 08 00 80 08 00 80 08 00 15 62 09 2c 63 c2 52 27 0a 80 08 00 80 08 00 80 08 00 15 62 09 2c 63 c2 52 27 0a 80 08 00 80 08 00 80 08 00 39 00 00 40 00 00 04 b0 02 71 98 39 00 00 40 00 00 37 98 14 c1 ee 2b 43 c2 52 67 0a 80 08 00 80 08 00 80 08 00 14 a1 f3 2b 43 c2 52 67 0f 80 08 00 80 08 00 80 08 00 14 d1 f9 2b 43 c2 52 67 0a 80 08 00 80 08 00 80 08 00 39 00 00 40 00 00 02 53 30 39 00 00 00 00 00 03 f0 a5 a5];
						mi,mdss-dsi-local-hbm-hlpm-white-110nit-command-state = "dsi_hs_mode";
						mi,mdss-dsi-local-hbm-hlpm-white-110nit-command = [39 00 00 40 00 00 03 f0 5a 5a 39 00 00 40 00 00 02 53 20 39 00 00 00 22 00 03 f0 a5 a5 39 00 00 40 00 00 03 f0 5a 5a 39 00 00 40 00 00 04 b0 03 87 92 39 00 00 40 00 00 11 92 02 00 00 00 00 00 19 a7 e4 29 e8 e8 21 c8 66 60 39 00 00 40 00 00 04 b0 02 b4 98 39 00 00 40 00 00 03 98 00 00 39 00 00 40 00 00 04 b0 01 75 98 39 00 00 40 00 00 13 98 00 40 14 02 80 52 0a 41 48 1c 27 ff 80 0f ff ff ff ff 39 00 00 40 00 00 04 b0 02 5f 98 39 00 00 40 00 00 13 98 00 40 6f 09 80 d1 11 d1 86 1c 21 c2 7f f8 00 ff ff ff 39 00 00 40 00 00 04 b0 01 61 98 39 00 00 40 00 00 06 98 07 78 9c 34 e9 39 00 00 40 00 00 04 b0 01 66 98 39 00 00 40 00 00 06 98 07 78 9c 34 e9 39 00 00 40 00 00 04 b0 01 70 98 39 00 00 40 00 00 06 98 09 9d ef ff 23 39 00 00 40 00 00 04 b0 01 bd 98 39 00 00 40 00 00 37 98 15 62 09 2c 63 c2 52 27 0a 80 08 00 80 08 00 80 08 00 15 62 09 2c 63 c2 52 27 0a 80 08 00 80 08 00 80 08 00 15 62 09 2c 63 c2 52 27 0a 80 08 00 80 08 00 80 08 00 39 00 00 40 00 00 04 b0 01 f3 98 39 00 00 40 00 00 37 98 15 62 09 2c 63 c2 52 27 0a 80 08 00 80 08 00 80 08 00 15 62 09 2c 63 c2 52 27 0a 80 08 00 80 08 00 80 08 00 15 62 09 2c 63 c2 52 27 0a 80 08 00 80 08 00 80 08 00 39 00 00 40 00 00 04 b0 02 71 98 39 00 00 40 00 00 37 98 14 c1 ee 2b 43 c2 52 67 0a 80 08 00 80 08 00 80 08 00 14 a1 f3 2b 43 c2 52 67 0f 80 08 00 80 08 00 80 08 00 14 d1 f9 2b 43 c2 52 67 0a 80 08 00 80 08 00 80 08 00 39 00 00 40 00 00 02 53 30 39 00 00 00 0a 00 03 f0 a5 a5];
						mi,mdss-dsi-local-hbm-normal-white-110nit-command-state = "dsi_hs_mode";
						mi,mdss-dsi-local-hbm-normal-white-110nit-command = [39 00 00 40 00 00 03 f0 5a 5a 39 00 00 40 00 00 04 b0 03 87 92 39 00 00 40 00 00 11 92 02 00 00 00 00 00 19 a7 e4 29 e8 e8 21 c8 66 60 39 00 00 40 00 00 04 b0 02 b4 98 39 00 00 40 00 00 03 98 00 00 39 00 00 40 00 00 04 b0 01 75 98 39 00 00 40 00 00 13 98 00 40 14 02 80 52 0a 41 48 1c 27 ff 80 0f ff ff ff ff 39 00 00 40 00 00 04 b0 02 5f 98 39 00 00 40 00 00 13 98 00 40 6f 09 80 d1 11 d1 86 1c 21 c2 7f f8 00 ff ff ff 39 00 00 40 00 00 04 b0 01 61 98 39 00 00 40 00 00 06 98 07 78 9c 34 e9 39 00 00 40 00 00 04 b0 01 66 98 39 00 00 40 00 00 06 98 07 78 9c 34 e9 39 00 00 40 00 00 04 b0 01 70 98 39 00 00 40 00 00 06 98 09 9d ef ff 23 39 00 00 40 00 00 04 b0 01 bd 98 39 00 00 40 00 00 37 98 15 62 09 2c 63 c2 52 27 0a 80 08 00 80 08 00 80 08 00 15 62 09 2c 63 c2 52 27 0a 80 08 00 80 08 00 80 08 00 15 62 09 2c 63 c2 52 27 0a 80 08 00 80 08 00 80 08 00 39 00 00 40 00 00 04 b0 01 f3 98 39 00 00 40 00 00 37 98 15 62 09 2c 63 c2 52 27 0a 80 08 00 80 08 00 80 08 00 15 62 09 2c 63 c2 52 27 0a 80 08 00 80 08 00 80 08 00 15 62 09 2c 63 c2 52 27 0a 80 08 00 80 08 00 80 08 00 39 00 00 40 00 00 04 b0 02 71 98 39 00 00 40 00 00 37 98 14 c1 ee 2b 43 c2 52 67 0a 80 08 00 80 08 00 80 08 00 14 a1 f3 2b 43 c2 52 67 0f 80 08 00 80 08 00 80 08 00 14 d1 f9 2b 43 c2 52 67 0a 80 08 00 80 08 00 80 08 00 39 00 00 40 00 00 02 53 30 39 00 00 00 00 00 03 f0 a5 a5];
						mi,mdss-dsi-local-hbm-hlpm-white-1000nit-command-state = "dsi_hs_mode";
						mi,mdss-dsi-local-hbm-hlpm-white-1000nit-command = [39 00 00 40 00 00 03 f0 5a 5a 39 00 00 40 00 00 02 53 20 39 00 00 00 22 00 03 f0 a5 a5 39 00 00 40 00 00 03 f0 5a 5a 39 00 00 40 00 00 04 b0 03 87 92 39 00 00 40 00 00 11 92 02 00 00 00 00 00 19 a7 e4 29 e8 e8 21 c8 66 60 39 00 00 40 00 00 04 b0 02 b4 98 39 00 00 40 00 00 03 98 00 00 39 00 00 40 00 00 04 b0 01 75 98 39 00 00 40 00 00 13 98 00 40 14 02 80 52 0a 41 48 1c 27 ff 80 0f ff ff ff ff 39 00 00 40 00 00 04 b0 02 5f 98 39 00 00 40 00 00 13 98 00 40 6f 09 80 d1 11 d1 86 1c 21 c2 7f f8 00 ff ff ff 39 00 00 40 00 00 04 b0 01 61 98 39 00 00 40 00 00 06 98 09 9d ef 7f 23 39 00 00 40 00 00 04 b0 01 66 98 39 00 00 40 00 00 06 98 09 9d ef 7f 23 39 00 00 40 00 00 04 b0 01 70 98 39 00 00 40 00 00 06 98 09 9d ef ff 23 39 00 00 40 00 00 04 b0 01 bd 98 39 00 00 40 00 00 37 98 15 62 09 2c 63 c2 52 27 0a 80 08 00 80 08 00 80 08 00 15 62 09 2c 63 c2 52 27 0a 80 08 00 80 08 00 80 08 00 15 62 09 2c 63 c2 52 27 0a 80 08 00 80 08 00 80 08 00 39 00 00 40 00 00 04 b0 01 f3 98 39 00 00 40 00 00 37 98 15 62 09 2c 63 c2 52 27 0a 80 08 00 80 08 00 80 08 00 15 62 09 2c 63 c2 52 27 0a 80 08 00 80 08 00 80 08 00 15 62 09 2c 63 c2 52 27 0a 80 08 00 80 08 00 80 08 00 39 00 00 40 00 00 04 b0 02 71 98 39 00 00 40 00 00 37 98 14 c1 ee 2b 43 c2 52 67 0a 80 08 00 80 08 00 80 08 00 14 a1 f3 2b 43 c2 52 67 0f 80 08 00 80 08 00 80 08 00 14 d1 f9 2b 43 c2 52 67 0a 80 08 00 80 08 00 80 08 00 39 00 00 40 00 00 02 53 30 39 00 00 00 0a 00 03 f0 a5 a5];
						mi,mdss-dsi-local-hbm-normal-white-1000nit-command-state = "dsi_hs_mode";
						mi,mdss-dsi-local-hbm-normal-white-1000nit-command-update = <0x51 0x16 0x02>;
						mi,mdss-dsi-local-hbm-normal-white-1000nit-command = <0x39000040 0x3f0 0x5a5a3900 0x400000 0x4b00387 0x92390000 0x40000011 0x92020000 0x19 0xa7e429e8 0xe821c866 0x60390000 0x40000004 0xb002b498 0x39000040 0x398 0x3900 0x400000 0x4b00175 0x98390000 0x40000013 0x98004014 0x280520a 0x41481c27 0xff800fff 0xffffff39 0x4000 0x4b002 0x5f983900 0x400000 0x13980040 0x6f0980d1 0x11d1861c 0x21c27ff8 0xffffff 0x39000040 0x4b0 0x1619839 0x4000 0x69809 0x9def7f23 0x39000040 0x4b0 0x1669839 0x4000 0x69809 0x9def7f23 0x39000040 0x4b0 0x1709839 0x4000 0x69809 0x9defff23 0x39000040 0x4b0 0x1bd9839 0x4000 0x379815 0x62092c63 0xc252270a 0x80080080 0x8008008 0x156209 0x2c63c252 0x270a8008 0x800800 0x80080015 0x62092c63 0xc252270a 0x80080080 0x8008008 0x390000 0x40000004 0xb001f398 0x39000040 0x3798 0x1562092c 0x63c25227 0xa800800 0x80080080 0x8001562 0x92c63c2 0x52270a80 0x8008008 0x800800 0x1562092c 0x63c25227 0xa800800 0x80080080 0x8003900 0x400000 0x4b00271 0x98390000 0x40000037 0x9814c1ee 0x2b43c252 0x670a8008 0x800800 0x80080014 0xa1f32b43 0xc252670f 0x80080080 0x8008008 0x14d1f9 0x2b43c252 0x670a8008 0x800800 0x80080039 0x4000 0x25330 0x39000040 0x351 0x3900 0x00 0x3f0a5a5>;
						mi,mdss-dsi-flat-mode-off-command-state = "dsi_lp_mode";
						mi,mdss-dsi-flat-mode-off-command = <0x39000040 0x3f0 0x5a5a3900 0x400000 0x4b00279 0x92150000 0x40000002 0x92053900 0x00 0x3f0a5a5>;
						mi,mdss-dsi-flat-mode-on-command-state = "dsi_lp_mode";
						mi,mdss-dsi-flat-mode-on-command = <0x39000040 0x3f0 0x5a5a3900 0x400000 0x4b00279 0x92150000 0x40000002 0x92253900 0x00 0x3f0a5a5>;
						mi,mdss-dsi-hbm-fod-off-command-state = "dsi_lp_mode";
						mi,mdss-dsi-hbm-fod-off-command-update = <0x51 0x01 0x02>;
						mi,mdss-dsi-hbm-fod-off-command = [39 00 00 40 00 00 03 f0 5a 5a 39 00 00 40 00 00 03 51 07 ff 15 00 00 40 00 00 02 f7 0f 39 00 00 00 00 00 03 f0 a5 a5];
						mi,mdss-dsi-hbm-fod-on-command-state = "dsi_lp_mode";
						mi,mdss-dsi-hbm-fod-on-command = [39 00 00 40 00 00 03 f0 5a 5a 39 00 00 40 00 00 03 51 0f ff 15 00 00 40 00 00 02 f7 0f 39 00 00 00 00 00 03 f0 a5 a5];
						mi,mdss-dsi-hbm-off-command-state = "dsi_lp_mode";
						mi,mdss-dsi-hbm-off-command-update = <0x51 0x01 0x02>;
						mi,mdss-dsi-hbm-off-command = [39 00 00 40 00 00 03 f0 5a 5a 39 00 00 40 00 00 03 51 07 ff 15 00 00 40 00 00 02 f7 0f 39 00 00 00 00 00 03 f0 a5 a5];
						mi,mdss-dsi-hbm-on-command-state = "dsi_lp_mode";
						mi,mdss-dsi-hbm-on-command = [39 00 00 40 00 00 03 f0 5a 5a 39 00 00 40 00 00 03 51 07 ff 15 00 00 40 00 00 02 f7 0f 39 00 00 00 00 00 03 f0 a5 a5];
						mi,mdss-dsi-dimmingoff-command-state = "dsi_hs_mode";
						mi,mdss-dsi-dimmingoff-command = [15 00 00 00 00 00 02 53 20];
						mi,mdss-dsi-dimmingon-command-state = "dsi_hs_mode";
						mi,mdss-dsi-dimmingon-command = [15 00 00 00 00 00 02 53 28];
						qcom,mdss-dsi-off-command-state = "dsi_lp_mode";
						qcom,mdss-dsi-off-command = [39 00 00 40 00 00 03 f0 5a 5a 05 00 00 00 14 00 02 28 00 39 00 00 40 00 00 04 b0 00 4e 98 39 00 00 40 00 00 04 98 01 09 80 39 00 00 40 00 00 04 b0 00 0f f6 15 00 00 40 00 00 02 f6 02 15 00 00 40 00 00 02 f7 0f 39 00 00 00 64 00 03 f0 a5 a5 05 00 00 00 78 00 02 10 00];
						qcom,mdss-dsc-block-prediction-enable;
						qcom,mdss-dsc-bit-per-pixel = <0x08>;
						qcom,mdss-dsc-bit-per-component = <0x08>;
						qcom,mdss-dsc-slice-per-pkt = <0x02>;
						qcom,mdss-dsc-slice-width = <0x21c>;
						qcom,mdss-dsc-slice-height = <0x28>;
						qcom,compression-mode = "dsc";
						qcom,mdss-dsi-nolp-command-state = "dsi_lp_mode";
						qcom,mdss-dsi-nolp-command-update = <0x51 0x07 0x02>;
						qcom,mdss-dsi-nolp-command = [39 00 00 40 00 00 03 f0 5a 5a 15 00 00 40 00 00 02 60 08 39 00 00 40 00 00 04 b0 00 30 bd 15 00 00 40 00 00 02 bd 01 39 00 00 40 00 00 04 b0 00 16 f2 39 00 00 40 00 00 03 f2 01 88 15 00 00 40 00 00 02 53 20 39 00 00 40 00 00 03 51 00 00 15 00 00 40 00 00 02 f7 0f 39 00 00 00 22 00 03 f0 a5 a5];
						qcom,mdss-dsi-timing-switch-command-state = "dsi_hs_mode";
						qcom,mdss-dsi-timing-switch-command = [39 00 00 40 00 00 03 f0 5a 5a 15 00 00 40 00 00 02 60 08 39 00 00 40 00 00 04 b0 00 30 bd 15 00 00 40 00 00 02 bd 01 39 00 00 40 00 00 04 b0 00 16 f2 39 00 00 40 00 00 03 f2 01 88 15 00 00 40 00 00 02 f7 0f 39 00 00 00 00 00 03 f0 a5 a5];
						qcom,mdss-dsi-on-command-state = "dsi_lp_mode";
						qcom,mdss-dsi-on-command = [39 00 00 00 00 00 5a 9e 11 00 00 89 30 80 09 d8 04 38 00 28 02 1c 02 1c 02 00 02 3b 00 20 03 92 00 07 00 0e 02 e0 02 8b 18 00 10 f0 03 0c 20 00 06 0b 0b 33 0e 1c 2a 38 46 54 62 69 70 77 79 7b 7d 7e 01 02 01 00 09 40 09 be 19 fc 19 fa 19 f8 1a 38 1a 78 1a b6 2a b6 2a f4 2a f4 4b 34 63 74 00 15 00 00 00 00 00 02 9d 01 05 00 00 00 78 00 02 11 00 15 00 00 00 00 00 02 35 00 39 00 00 40 00 00 05 2a 00 00 04 37 39 00 00 00 00 00 05 2b 00 00 09 5f 39 00 00 40 00 00 03 f0 5a 5a 15 00 00 40 00 00 02 60 08 39 00 00 40 00 00 04 b0 00 30 bd 15 00 00 40 00 00 02 bd 01 39 00 00 40 00 00 04 b0 00 16 f2 39 00 00 40 00 00 03 f2 01 88 15 00 00 40 00 00 02 f7 0f 39 00 00 00 00 00 03 f0 a5 a5 39 00 00 40 00 00 03 f0 5a 5a 39 00 00 40 00 00 04 b0 00 36 c5 15 00 00 40 00 00 02 c5 11 39 00 00 40 00 00 04 b0 00 3a c5 39 00 00 40 00 00 03 c5 3f 21 39 00 00 40 00 00 04 b0 00 52 c5 39 00 00 40 00 00 03 c5 3f 21 39 00 00 00 00 00 03 f0 a5 a5 39 00 00 40 00 00 03 f0 5a 5a 39 00 00 40 00 00 04 b0 00 0d 94 15 00 00 40 00 00 02 94 20 15 00 00 40 00 00 02 53 28 39 00 00 40 00 00 03 51 00 00 15 00 00 40 00 00 02 f7 0f 39 00 00 00 00 00 03 f0 a5 a5 39 00 00 40 00 00 03 f0 5a 5a 15 00 00 40 00 00 02 e5 15 39 00 00 40 00 00 04 b0 00 3d f4 15 00 00 40 00 00 02 f4 f0 39 00 00 40 00 00 05 ed 43 49 42 03 39 00 00 00 00 00 03 f0 a5 a5 39 00 00 40 00 00 03 f0 5a 5a 39 00 00 40 00 00 04 b0 00 0a b1 39 00 00 40 00 00 04 b1 18 48 20 39 00 00 00 00 00 03 f0 a5 a5 39 00 00 40 00 00 03 f0 5a 5a 39 00 00 40 00 00 04 b0 01 64 92 39 00 00 40 00 00 02 92 70 39 00 00 00 00 00 03 f0 a5 a5 39 00 00 40 00 00 03 f0 5a 5a 39 00 00 40 00 00 04 b0 02 7e 92 15 00 00 40 00 00 02 92 0f 39 00 00 00 00 00 03 f0 a5 a5 39 00 00 40 00 00 03 f0 5a 5a 39 00 00 40 00 00 02 bb 30 39 00 00 40 00 00 02 f7 0f 39 00 00 00 00 00 03 f0 a5 a5 39 00 00 40 00 00 03 f0 5a 5a 39 00 00 40 00 00 04 b0 00 20 f6 15 00 00 40 00 00 02 f6 f0 39 00 00 00 00 00 03 f0 a5 a5 39 00 00 40 00 00 03 f0 5a 5a 39 00 00 40 00 00 04 b0 00 4e 98 39 00 00 40 00 00 04 98 00 09 80 39 00 00 40 00 00 04 b0 00 0f f6 15 00 00 40 00 00 02 f6 10 39 00 00 00 14 00 02 f7 0f 05 00 00 40 00 00 02 29 00 39 00 00 00 00 00 03 f0 a5 a5];
						qcom,mdss-mdp-transfer-time-us = <0x1c84>;
						qcom,mdss-dsi-panel-jitter = <0x05 0x01>;
						qcom,mdss-dsi-panel-clockrate = <0x4190ab00>;
						qcom,mdss-dsi-v-bottom-border = <0x00>;
						qcom,mdss-dsi-v-top-border = <0x00>;
						qcom,mdss-dsi-h-right-border = <0x00>;
						qcom,mdss-dsi-h-left-border = <0x00>;
						qcom,mdss-dsi-h-sync-pulse = <0x00>;
						qcom,mdss-dsi-v-pulse-width = <0x18>;
						qcom,mdss-dsi-v-front-porch = <0x80>;
						qcom,mdss-dsi-v-back-porch = <0x84>;
						qcom,mdss-dsi-h-sync-skew = <0x00>;
						qcom,mdss-dsi-h-pulse-width = <0x20>;
						qcom,mdss-dsi-h-back-porch = <0x7c>;
						qcom,mdss-dsi-h-front-porch = <0x7c>;
						qcom,mdss-dsi-panel-height = <0x960>;
						qcom,mdss-dsi-panel-width = <0x438>;
						qcom,mdss-dsi-panel-framerate = <0x5a>;
						qcom,mdss-dsi-cmd-mode;
					};
				};
			};
